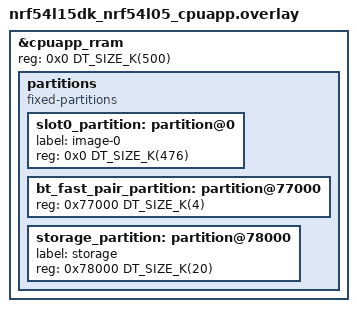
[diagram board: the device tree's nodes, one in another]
/*
 * Copyright (c) 2026 Nordic Semiconductor ASA
 *
 * SPDX-License-Identifier: LicenseRef-Nordic-5-Clause
 */

&cpuapp_rram {
	/* Application does not use cpuflpr core. Assign whole RRAM to cpuapp. */
	reg = <0x0 DT_SIZE_K(500)>;

	/* Redefine the "partitions" DTS node. */
	/delete-node/ partitions;

	partitions {
		compatible = "fixed-partitions";
		#address-cells = <1>;
		#size-cells = <1>;

		slot0_partition: partition@0 {
			label = "image-0";
			reg = <0x0 DT_SIZE_K(476)>;
		};

		bt_fast_pair_partition: partition@77000 {
			reg = <0x77000 DT_SIZE_K(4)>;
		};

		storage_partition: partition@78000 {
			label = "storage";
			reg = <0x78000 DT_SIZE_K(20)>;
		};
	};
};
